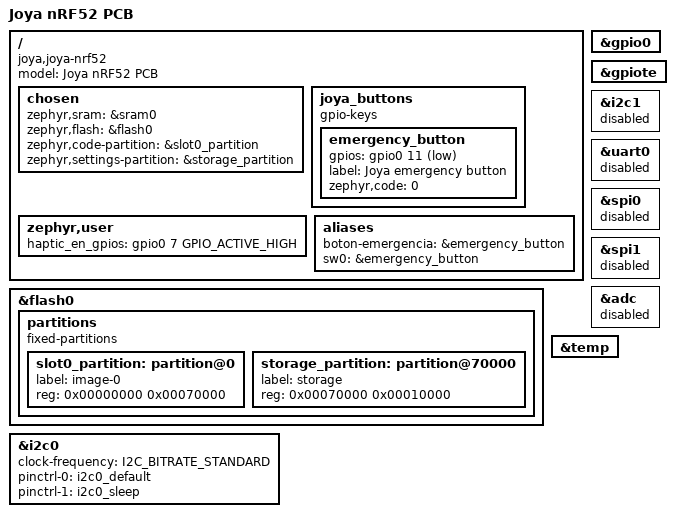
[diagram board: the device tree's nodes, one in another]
/dts-v1/;

#include <nordic/nrf52832_qfaa.dtsi>

#include <zephyr/dt-bindings/gpio/gpio.h>
#include <zephyr/dt-bindings/i2c/i2c.h>

#include "joya_nrf52-pinctrl.dtsi"

/ {
	model = "Joya nRF52 PCB";
	compatible = "joya,joya-nrf52";

	chosen {
		zephyr,sram = &sram0;
		zephyr,flash = &flash0;
		zephyr,code-partition = &slot0_partition;
		zephyr,settings-partition = &storage_partition;
	};

	joya_buttons {
		compatible = "gpio-keys";

		/* GPIO 11 for production, GPIO 13 for development */
		emergency_button: emergency_button {
			gpios = <&gpio0 11 (GPIO_PULL_UP | GPIO_ACTIVE_LOW)>;
			label = "Joya emergency button";
			zephyr,code = <0>;
		};
	};

	zephyr,user {
		haptic_en_gpios = <&gpio0 7 GPIO_ACTIVE_HIGH>;
	};

	aliases {
		boton-emergencia = &emergency_button;
		sw0 = &emergency_button;
	};
};

&flash0 {
	partitions {
		compatible = "fixed-partitions";
		#address-cells = <1>;
		#size-cells = <1>;

		slot0_partition: partition@0 {
			label = "image-0";
			reg = <0x00000000 0x00070000>;
		};

		storage_partition: partition@70000 {
			label = "storage";
			reg = <0x00070000 0x00010000>;
		};
	};
};

&gpio0 {
	status = "okay";
};

&gpiote {
	status = "okay";
};

&i2c0 {
	status = "okay";
	clock-frequency = <I2C_BITRATE_STANDARD>;
	pinctrl-0 = <&i2c0_default>;
	pinctrl-1 = <&i2c0_sleep>;
	pinctrl-names = "default", "sleep";
};

&i2c1 {
	status = "disabled";
};

&uart0 {
	status = "disabled";
};

&spi0 {
	status = "disabled";
};

&spi1 {
	status = "disabled";
};

&adc {
	status = "disabled";
};

&temp {
	status = "okay";
};
